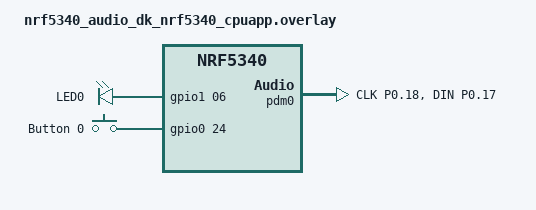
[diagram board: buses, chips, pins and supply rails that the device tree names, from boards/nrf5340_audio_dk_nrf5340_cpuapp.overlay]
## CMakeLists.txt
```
cmake_minimum_required(VERSION 3.20.0)
# Define DT Overlay:
# Prototype 1: mic_patch_mk1_nrf5340_cpuapp.overlay
# Prototype 2: mic_patch_mk2_nrf5340_cpuapp.overlay
#set(DTC_OVERLAY_FILE "${CMAKE_CURRENT_SOURCE_DIR}/boards/mic_patch_mk1_nrf5340_cpuapp.overlay")

find_package(Zephyr REQUIRED HINTS $ENV{ZEPHYR_BASE})

project(nrf_auscultation)

set(NRF5340_NETWORK_CORE_IMAGE hci_ipc)

target_sources(app PRIVATE src/main.c)
target_sources(app PRIVATE src/event_handler.c)
target_sources(app PRIVATE src/audio/wav_file.c)
target_sources(app PRIVATE src/modules/sd_card.c)
target_sources(app PRIVATE src/modules/button_handler.c)
target_sources(app PRIVATE src/modules/led_controller.c)
target_sources(app PRIVATE src/audio/audio_stream.c)
target_sources(app PRIVATE src/audio/audio_in.c)

#DSP
target_sources(app PRIVATE src/audio/dsp/circular_block_buffer.c)
target_sources(app PRIVATE src/audio/dsp/rt_peak_detector.c)
target_sources(app PRIVATE src/audio/dsp/peak_validator.c)
target_sources(app PRIVATE src/audio/dsp/peak_processor.c)
target_sources(app PRIVATE src/audio/dsp/window_analysis.c)
target_sources(app PRIVATE src/audio/dsp/trend_analysis.c)

target_sources(app PRIVATE src/ble/ble_manager.c)
target_sources(app PRIVATE src/ble/heart_service.c)
```

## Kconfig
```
#
# Copyright (c) 2018 Nordic Semiconductor ASA
#
# SPDX-License-Identifier: LicenseRef-Nordic-5-Clause
#

menu "Heart Patch Modes"

config HEART_PATCH_DSP_MODE
    bool "Enable DSP processing mode"
    default y
    help
      Select this to enable DSP feature processing.
      Disable to use Download/Raw Audio mode.
endmenu

menu "SD enable mode"

config SD_CARD_SUPPORT
    bool "Enable SD card support"
    default n
    help
      Enable SD card recording and storage features.
endmenu

menuconfig NRF5340_AUDIO
	 bool "nRF5340 Audio [EXPERIMENTAL]"
	 select EXPERIMENTAL

if NRF5340_AUDIO

config AUDIO_DEV
	int "Select which device type to compile for. 1=HEADSET or 2=GATEWAY"
	range 1 2
	default 1
	help
	  Setting this variable to 1 selects that the project is compiled
	  as a HEADSET device.
	  Setting to 2 will compile as a GATEWAY.

choice NRF5340_AUDIO_TRANSPORT_MODE
	prompt "Choose BIS or CIS for ISO transport"
	default TRANSPORT_CIS if WALKIE_TALKIE_DEMO
	default TRANSPORT_CIS

config TRANSPORT_BIS
	bool "Use BIS (Broadcast Isochronous Stream)"

config TRANSPORT_CIS
	bool "Use CIS (Connected Isochronous Stream)"

endchoice

#----------------------------------------------------------------------------#
#rsource "Kconfig.defaults"
#rsource "src/audio/Kconfig"
#rsource "src/bluetooth/Kconfig"
#rsource "src/drivers/Kconfig"
rsource "src/modules/Kconfig"
#rsource "src/utils/Kconfig"
#rsource "dfu/conf/Kconfig.dfu"

#----------------------------------------------------------------------------#
menu "Logging"

module = MAIN
module-str = main
source "subsys/logging/Kconfig.template.log_config"

config PRINT_STACK_USAGE_MS
	depends on THREAD_ANALYZER && INIT_STACKS
	int "Print stack usage every x milliseconds"
	default 5000

endmenu # Log levels

#----------------------------------------------------------------------------#
endif # NRF5340_AUDIO

source "Kconfig.zephyr"
```

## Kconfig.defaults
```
#
# Copyright (c) 2022 Nordic Semiconductor ASA
#
# SPDX-License-Identifier: LicenseRef-Nordic-5-Clause
#

config REBOOT
	default y

config MAIN_THREAD_PRIORITY
	default 10

config MAIN_STACK_SIZE
	default 1800 if SD_CARD_PLAYBACK
	default 1600

config SYSTEM_WORKQUEUE_STACK_SIZE
	default 1200

# As long as thread names are used, config must be set to "y"
config THREAD_NAME
	default y

config NCS_INCLUDE_RPMSG_CHILD_IMAGE
	default !BT_LL_ACS_NRF53

# Workaround to not use fatal_error.c in NCS. Note that the system may still
# reset on error depending on the build configuraion
config RESET_ON_FATAL_ERROR
	default n

# Default Config for Debug and Release build
config HW_CODEC_CIRRUS_LOGIC
	default n

config BT
	default n

config BOARD_ENABLE_DCDC_APP
	default n

config BOARD_ENABLE_DCDC_NET
	default n

config BOARD_ENABLE_CPUNET
	default n

config NFCT_PINS_AS_GPIOS
	default n

config ZBUS
	default n

config ZBUS_RUNTIME_OBSERVERS
	default n

config ZBUS_MSG_SUBSCRIBER
	default n

config SENSOR
	default n

config REGULATOR
	default n

config CONTIN_ARRAY
	default n

config NRFX_I2S0
	default n

config PCM_MIX
	default n

config TONE
	default n

config PSCM
	default n

config DATA_FIFO
	default n

# Enable NRFX_CLOCK for ACLK control
config NRFX_CLOCK
	default y

config I2C
	default y

choice LIBC_IMPLEMENTATION
	# NOTE: Since we are not using minimal libc, error codes from
	#       minimal libc are not used
	default NEWLIB_LIBC
endchoice

# Audio codec LC3 related defines
# FPU_SHARING enables preservation of the hardware floating point registers
# across context switches to allow multiple threads to perform concurrent
# floating point operations.
config FPU
	default y

config FPU_SHARING
	default y

# Enable SDHC interface
config DISK_DRIVERS
	default y

config DISK_DRIVER_SDMMC
	default y

# Enable SPI interface
config SPI
	default y

# Enable ADC for board version readback
config ADC
	default y

# Allocate buffer on RAM for transferring chunck of data
# from Flash to SPI
config SPI_NRFX_RAM_BUFFER_SIZE
	default 8

# Config the file system
config FILE_SYSTEM
	default y

config FAT_FILESYSTEM_ELM
	default y

config FS_FATFS_LFN
	default y
choice FS_FATFS_LFN_MODE
	# Using stack for LFN work queue
	default FS_FATFS_LFN_MODE_STACK
endchoice

# exFAT enabled to support longer file names and higher transfer speed
config FS_FATFS_EXFAT
	default y

# Set the maximum file name length to 255
config FS_FATFS_MAX_LFN
	default 255

config BT_LL_ACS_NRF53
	default y

config WATCHDOG
	default y

config TASK_WDT
	default y
```

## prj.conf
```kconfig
#Custom Board configuration:
CONFIG_HEART_PATCH_DSP_MODE=y #Yes for regular operation DSP mode, no for BLE stream audio mode
CONFIG_SD_CARD_SUPPORT=y #Enable SD card, supported in prototype 1

CONFIG_AUDIO_DMIC=y
CONFIG_AUDIO=y
CONFIG_DMA=y
CONFIG_GPIO=y

# Enable RTT as the console and log backend
CONFIG_RTT_CONSOLE=y
CONFIG_USE_SEGGER_RTT=y
CONFIG_LOG_BACKEND_RTT=y
CONFIG_LOG_PRINTK=y

# Set RTT to non-blocking mode 
CONFIG_SEGGER_RTT_MODE_NO_BLOCK_SKIP=y
CONFIG_LOG_BACKEND_RTT_MODE_DROP=y

# Disable UART console/logging
CONFIG_UART_CONSOLE=n
CONFIG_LOG_BACKEND_UART=n

# Enable Zephyr logging
CONFIG_LOG=y
CONFIG_LOG_MODE_MINIMAL=y
CONFIG_DEBUG=y
CONFIG_CBPRINTF_FP_SUPPORT=y

# Config SD Card
CONFIG_FILE_SYSTEM=y
CONFIG_FAT_FILESYSTEM_ELM=y
CONFIG_DISK_ACCESS=y
CONFIG_MAIN_STACK_SIZE=16384 
CONFIG_DISK_DRIVER_SDMMC=y
CONFIG_SDMMC_STACK=y

CONFIG_NCS_SAMPLES_DEFAULTS=y

# Config BLE
# Core BLE support on app core
CONFIG_BT=y
CONFIG_BT_PERIPHERAL=y
CONFIG_BT_DEVICE_NAME="Heart Patch"

# Optional BLE LBS Service
CONFIG_BT_LBS=y
CONFIG_BT_LBS_POLL_BUTTON=y

# BLE Security 
CONFIG_BT_SMP=y

# BLE Flash and settings
CONFIG_BT_HCI=y
CONFIG_BT_SETTINGS=n
CONFIG_SETTINGS=n
CONFIG_FLASH=y
CONFIG_FLASH_PAGE_LAYOUT=y
CONFIG_FLASH_MAP=y
# CONFIG_NVS=y 

#BT Data Length Extension
CONFIG_BT_GATT_CLIENT=y
CONFIG_BT_USER_DATA_LEN_UPDATE=y
CONFIG_BT_CTLR_DATA_LENGTH_MAX=251
CONFIG_BT_BUF_ACL_RX_SIZE=251
CONFIG_BT_BUF_ACL_TX_SIZE=251
CONFIG_BT_L2CAP_TX_MTU=247

#CMSIS DSP
CONFIG_NEWLIB_LIBC=y
CONFIG_CMSIS_DSP=y
CONFIG_CMSIS_DSP_STATISTICS=y
CONFIG_CMSIS_DSP_TRANSFORM=y
CONFIG_CMSIS_DSP_FILTERING=y
CONFIG_CMSIS_DSP_COMPLEXMATH=y
```

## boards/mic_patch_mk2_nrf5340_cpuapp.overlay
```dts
/ {
    aliases {
        led0 = &board_led0;
        sw0  = &board_button0;
 
    };

    leds {
        compatible = "gpio-leds";

        board_led0: led_0 {
            gpios = <&gpio1 06 GPIO_ACTIVE_HIGH>;
            label = "LED0";
        };
    };

    buttons {
        compatible = "gpio-keys";

        board_button0: button_0 {
            gpios = <&gpio0 24 GPIO_ACTIVE_HIGH>;
            label = "Button 0";
        };

    };
};

&clock {
    hfclkaudio-frequency = <12288000>;  // 12.288 MHz
};

&pinctrl {
	pdm0_default_alt: pdm0_default_alt {
		group1 {
			psels = <NRF_PSEL(PDM_CLK, 0, 18)>,
				<NRF_PSEL(PDM_DIN, 0, 17)>;
		};
	};
};

dmic_dev: &pdm0 {
	status = "okay";
	pinctrl-0 = <&pdm0_default_alt>;
	pinctrl-names = "default";
	clock-source = "ACLK";
};
```

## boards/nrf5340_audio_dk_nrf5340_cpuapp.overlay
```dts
/ {
    aliases {
        led0 = &board_led0;
        sw0  = &board_button0;
        //sw1  = &board_button1; 
        //spi-sd = &spi2;
    };

    leds {
        compatible = "gpio-leds";

        board_led0: led_0 {
            gpios = <&gpio1 06 GPIO_ACTIVE_HIGH>;
            label = "LED0";
        };
    };

    buttons {
        compatible = "gpio-keys";

        board_button0: button_0 {
            gpios = <&gpio0 24 GPIO_ACTIVE_HIGH>;
            label = "Button 0";
        };

        // board_button1: button_1 {
        //     gpios = <&gpio0 17 GPIO_ACTIVE_HIGH>;
        //     label = "Button 1";
        // };
    };
};

// &spi2 {
//     compatible = "nordic,nrf-spim";
//     status = "okay";
//     pinctrl-0 = <&spi2_sd_pins>;
//     pinctrl-names = "default";
//     cs-gpios = <&gpio0 15 GPIO_ACTIVE_LOW>;  // CS index 0

//     board_sdhc0: sdhc@0 {
//         compatible = "zephyr,sdhc-spi-slot";
//         reg = <0>;
//         status = "okay";

//         sdmmc {
//             compatible = "zephyr,sdmmc-disk";
//             status = "okay";
//             label = "SD";  
//         };

//         spi-max-frequency = <1000000>;
//     };
// };

// &pinctrl {
//     spi2_sd_pins: spi2_sd_pins {
//         group1 {
//             psels = <NRF_PSEL(SPIM_SCK, 0, 8)>,
//                     <NRF_PSEL(SPIM_MOSI, 0, 9)>,
//                     <NRF_PSEL(SPIM_MISO, 0, 10)>;
//         };
//     };
// };


&clock {
    hfclkaudio-frequency = <12288000>;  // 12.288 MHz
};

&pinctrl {
	pdm0_default_alt: pdm0_default_alt {
		group1 {
			psels = <NRF_PSEL(PDM_CLK, 0, 18)>,
				<NRF_PSEL(PDM_DIN, 0, 17)>;
		};
	};
};

dmic_dev: &pdm0 {
	status = "okay";
	pinctrl-0 = <&pdm0_default_alt>;
	pinctrl-names = "default";
	clock-source = "ACLK";
};

&uart1 {
    status = "disabled";
};
```

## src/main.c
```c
#include <zephyr/kernel.h>
#include <zephyr/drivers/gpio.h>
#include <zephyr/logging/log.h>
#include "modules/button_handler.h"
#include "modules/led_controller.h"
#ifdef CONFIG_SD_CARD_SUPPORT
#include "modules/sd_card.h"
#endif
#include "audio/wav_file.h"
#include "audio/audio_in.h"
#include "audio/audio_stream.h"
#include <zephyr/drivers/gpio.h>
#include <zephyr/audio/dmic.h>
#include "macros.h"
#include "event_handler.h"
#include "ble/ble_manager.h"
#include "audio/dsp/rt_peak_detector.h"
#include "audio/dsp/circular_block_buffer.h"
#include "audio/dsp/peak_processor.h"
#include "audio/dsp/window_analysis.h"

LOG_MODULE_REGISTER(main);

int main(void)
{
    int ret;
	LOG_INF("Turning on");

	static struct fs_file_t output_wav_file;

	WavConfig output_wav_config = {
			.wav_file = &output_wav_file,
			.file_name = "test.wav",
			.length = WAV_LENGTH_BLOCKS * MAX_BLOCK_SIZE,
			.sample_rate = MAX_SAMPLE_RATE,
			.bytes_per_sample = BYTES_PER_SAMPLE,
			.num_channels = NUM_CHANNELS,
	};

	static struct fs_file_t input_wav_file;

	WavConfig input_wav_config = {
			.wav_file = &input_wav_file,
			.file_name = "tri16muf.wav",
	};

	AudioInConfig audio_in_config = {
		.audio_input_type = AUDIO_INPUT_TYPE_PDM,
		.input_wav_config = input_wav_config,
		.output_wav_config = output_wav_config,
		.dmic_ctx = DEVICE_DT_GET(DT_NODELABEL(pdm0)),
		.pdm_gain = NRF_PDM_GAIN_MAXIMUM,
		.msgq = audio_stream_get_msgq(),
	};

	RTPeakConfig rt_peak_config = {
		.block_size = BLOCK_SIZE_SAMPLES,   
		.num_blocks = CB_NUM_BLOCKS,   
		.alpha = 0.0001,
		.threshold_scale = 2.0,
		.min_distance_samples = 2000,        
	};

	RTPeakValConfig rt_peak_val_config = {
		.close_r = 0.45,
		.far_r = 0.55,
		.margin = 0.05,
		.peak_msgq = audio_stream_get_peak_msgq()
	};

	PeakProcessorConfig peak_processor_config = {
		.pre_ratio = 0.25,
		.pre_max_samples = 2000,
		.pre_min_samples = 200,
	};

	WindowAnalysisConfig window_analysis_config = {
		.audio_hl_thresh = 1.0f / 3.0f,
		.ste_block_size_samples = STE_SAMPLES_PER_BLOCK,
		.ste_hl_thresh = 0.4,
		.peak_thresh_scale = 0.7,
		.peak_min_distance = 1,
		.de_cluster_window_r = 0.2,
		.ident_s1_reject_r = 0.3,
		.ident_s1_s2_gap_r = 0.29,
		.ident_s1_s2_gap_tol = 0.15,
		.hs_window_size = HS_WINDOW_SIZE,

		//Trend analysis
	    .ta_rms_buf_size = TREND_ANALYSER_MAX_BUFFER,
    	.ta_rms_slope_thresh = -0.015,
    	.ta_rms_min_windows = 15,

    	.ta_centroid_buf_size = TREND_ANALYSER_MAX_BUFFER,
   		.ta_centroid_slope_thresh = -1.8,
    	.ta_centroid_min_windows = 15,
	};

	AudioStreamConfig audio_stream_config = {
		.rt_peak_config = rt_peak_config,
		.rt_peak_val_config = rt_peak_val_config,
		.peak_processor_config = peak_processor_config,
		.window_analysis_config = window_analysis_config,
	};

	ret = button_handler_init();
	if(ret!=0) LOG_ERR("Buttons failed to init");
    ret = led_controller_init();
	if(ret!=0) LOG_ERR("LEDs failed to init");

    LOG_INF("Configured Buttons & Interrupts");

	ret = audio_in_init(audio_in_config);
	if(ret!=0) LOG_ERR("Audio In Config Failed");
	
    #if IS_ENABLED(CONFIG_SD_CARD_SUPPORT) 
    ret = sd_card_init();
	if(ret!=0) LOG_ERR("SD Failed to init");
	#endif

	ret = ble_init();
	if(ret!=0) LOG_ERR("BLE Failed to init");

	init_audio_stream(audio_stream_config);

    // Start up the application
    AppEvent ev = { .type = EVENT_START_UP};
    event_handler_post(ev);
	
    LOG_INF("Entering main event loop…");
    event_handler_run();
}
```

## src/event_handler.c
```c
#include "event_handler.h"
#include <zephyr/kernel.h>
#include <zephyr/logging/log.h>
#include "modules/led_controller.h"
#include "ble/ble_manager.h"
#include "ble/heart_service.h"
#include "audio/audio_in.h"
#include "audio/audio_stream.h"

LOG_MODULE_REGISTER(event_handler);

K_MSGQ_DEFINE(_event_queue, sizeof(AppEvent), 8, 4);
K_SEM_DEFINE(_event_sem, 0, 1);

typedef enum {
    STATE_IDLE,
    STATE_ADVERTISING,
    STATE_CONNECTED,
    STATE_STREAMING
} AppState;

static AppState app_state = STATE_IDLE;
//static AudioStream *audio_stream_ptr = NULL;

// void event_handler_set_audio_stream(AudioStream *audio_stream) {
//     audio_stream_ptr = audio_stream;
// }

void event_handler_post(AppEvent evt)
{
    k_msgq_put(&_event_queue, &evt, K_NO_WAIT);
    k_sem_give(&_event_sem);
}

void _send_demo_heartbeat_packet()
{
    static float counter = 0.0f;
    struct heart_packet pkt = {
        .rms = 10.0f + counter,
        .centroid = 200.0f + counter,
        .timestamp_ms = k_uptime_get()
    };

    counter =  counter + 1.0f;

    int err = bt_heart_service_notify_packet(&pkt);
    if (err) {
        printk("Failed to send packet: %d\n", err);
    } else {
        printk("Demo heartbeat packet sent!\n");
    }
}

#if !IS_ENABLED(CONFIG_HEART_PATCH_DSP_MODE)
void _transmit_audio_ble() {
    //Send Via BLE
    const int16_t *buf = get_audio_buffer();
    size_t len_samples = get_audio_buffer_length();

    if (buf && len_samples > 0) {
        size_t len_bytes = len_samples * sizeof(int16_t);
        int ret = transmit_audio_buffer((const uint8_t *)buf, len_bytes);
        if (ret) {
            LOG_ERR("Failed to transmit audio buffer: %d", ret);
        } else {
            LOG_INF("Audio buffer transmitted successfully.");
        }
        } else {
        LOG_WRN("No audio buffer available to transmit.");
    }
}
#endif

//===========================================FSM State function wrappers===================================
void _advertise() {
    //led_controller_on();
    led_controller_start_blinking(K_MSEC(500));
    ble_advertise();
    app_state = STATE_ADVERTISING;
}

void _connect() {
    led_controller_stop_blinking();
    led_controller_on();
    //led_set_mode(LED_OFF);
    app_state = STATE_CONNECTED;
}

void _read_in_audio() {
    led_controller_start_blinking(K_MSEC(150));
    audio_in_start();
    #if !IS_ENABLED(CONFIG_HEART_PATCH_DSP_MODE)
        _transmit_audio_ble();
    #endif
    led_controller_stop_blinking();
    led_controller_on();
}

// int _read_wav() {
//     static struct fs_file_t read_wav_file;
//         WavConfig read_wav_config = {
//         .wav_file = &read_wav_file,
//         .file_name = "00000000.wav",
//     };
//     led_controller_start_blinking(K_MSEC(150));
//     int ret = open_wav_for_read(&read_wav_config);
//     if (ret == 0) {
//         printk("WAV: %d Hz, %d ch, %d bits/sample\n",
//             read_wav_config.header.sample_rate,
//             read_wav_config.header.num_channels,
//             read_wav_config.header.bit_depth);
//     }
//     producer_capture_audio_from_wav(&read_wav_config);
//     // Now read audio blocks as needed!
//     //capture_audio(audio_stream_ptr);
//     return ret;
//}


//========================================================================================================

static void handle_event(AppEvent evt)
{
    int ret;
    switch (app_state) {
        case STATE_IDLE:
            if (evt.type == EVENT_BUTTON_0_PRESS) {
                _advertise();
            }
            break;
        case STATE_ADVERTISING:
            if (evt.type == EVENT_BLE_CONNECTED) {
                _connect();
            }
            break;

        case STATE_CONNECTED:
            //Send Dummy BLE Data
            if (evt.type == EVENT_BUTTON_0_PRESS) {
                _send_demo_heartbeat_packet();
                ret = bt_heart_service_notify_alert(0x02);
                if(ret!=0) LOG_ERR("Alert Failed to send");
            }
            //Record Audio to SD Card and then stream over BLE
            if (evt.type == EVENT_BLE_RECORD) {
                _read_in_audio();
            }
            // if (evt.type = EVENT_BLE_DISCONNECTED) {
            //     app_state = STATE_IDLE;
            //     led_controller_off();
            // }
            break;

        case STATE_STREAMING:
            // if (evt.type == EVENT_AUDIO_FINISHED) {
            //     //audio_stop();
            //     //led_set_mode(LED_OFF);
            //     app_state = STATE_CONNECTED;
            // }
            led_controller_start_blinking(K_MSEC(500));
            app_state = STATE_IDLE;
            break;
        }
}

int event_handler_run(void)
{
    LOG_INF("Starting event handler loop");

    while (1) {
        k_sem_take(&_event_sem, K_FOREVER);
        AppEvent evt;
        while (k_msgq_get(&_event_queue, &evt, K_NO_WAIT) == 0) {
            handle_event(evt);
        }
    }

    return 0;
}
```

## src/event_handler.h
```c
#ifndef EVENT_HANDLER_H_
#define EVENT_HANDLER_H_

//#include "audio/audio_stream.h"

int event_handler_run(void);  

typedef enum {
    EVENT_START_UP,
    EVENT_BUTTON_0_PRESS,
    EVENT_BUTTON_1_PRESS,
    EVENT_BLE_CONNECTED,
    EVENT_BLE_DISCONNECTED,
    EVENT_AUDIO_FINISHED,
    EVENT_BLE_START_STREAMING,
    EVENT_BLE_STOP_STREAMING,
    EVENT_BLE_TOGGLE_LED,
    EVENT_BLE_RECORD,
    EVENT_BLE_TRANSMIT,
} AppEventType;

typedef struct {
    AppEventType type;
    void *data;  
} AppEvent;

void event_handler_post(AppEvent evt);


#endif
```

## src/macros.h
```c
#ifndef _MACROS_H_
#define _MACROS_H_

//Device Tree Aliases:
#define LED0_NODE DT_ALIAS(led0)
#define SW0_NODE DT_ALIAS(sw0)
#define SW1_NODE DT_ALIAS(sw1)

#define MAX_SAMPLE_RATE  16000
#define SAMPLE_BIT_WIDTH 16
#define BYTES_PER_SAMPLE 2
#define NUM_CHANNELS 1
#define READ_TIMEOUT 1000

#if CONFIG_HEART_PATCH_DSP_MODE
#define WAV_LENGTH_BLOCKS 200 //Length of capture, 200 = 20s at 16Khz fs
#else
#define WAV_LENGTH_BLOCKS 50  //5s for BLE transmission
#endif

#define BLOCK_SIZE(_sample_rate, _number_of_channels) \
(BYTES_PER_SAMPLE * (_sample_rate / 10) * _number_of_channels)

#define MAX_BLOCK_SIZE  BLOCK_SIZE(MAX_SAMPLE_RATE, NUM_CHANNELS)
#define BLOCK_SIZE_SAMPLES MAX_BLOCK_SIZE / 2

#define MAX_FILENAME_LEN 16

//DSP 
//Circular Buffer
#define CB_NUM_BLOCKS 20
#define CB_BLOCK_SAMPLES BLOCK_SIZE_SAMPLES

//Peak Processor
#define PP_MAX_WINDOW_LEN CB_NUM_BLOCKS * CB_BLOCK_SAMPLES

//Window Analysis
#define STE_SAMPLES_PER_BLOCK 160 // 160 at 16khz = 10ms
#define STE_MAX_BUF_LEN PP_MAX_WINDOW_LEN / STE_SAMPLES_PER_BLOCK
#define MAX_NUM_WINDOW_PEAKS 64
#define HS_WINDOW_SIZE 512

#define TREND_ANALYSER_MAX_BUFFER 30

#ifndef M_PI
#define M_PI 3.14159265358979323846f
#endif

#endif
```
